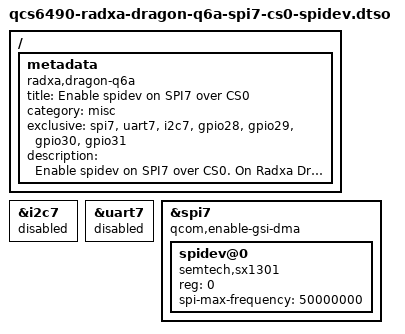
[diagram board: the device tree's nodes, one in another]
// SPDX-License-Identifier: BSD-3-Clause
/*
 * Copyright (c) 2025 Radxa Computer (Shenzhen) Co., Ltd.
 */

/dts-v1/;
/plugin/;

/ {
    metadata {
        title = "Enable spidev on SPI7 over CS0";
        compatible = "radxa,dragon-q6a";
        category = "misc";
        exclusive = "spi7", "uart7", "i2c7", "gpio28", "gpio29", "gpio30", "gpio31";
        description = "Enable spidev on SPI7 over CS0. 
On Radxa Dragon Q6A, this is pin 11(mosi), 29(cs0), 31(miso), 32(sclk).";
    };
};

&i2c7 {
	status = "disabled";
};

&uart7 {
	status = "disabled";
};

&spi7 {
	qcom,enable-gsi-dma;
	status = "okay";
	
	spidev@0 {
		compatible = "semtech,sx1301";
		status = "okay";
		reg = <0>;
		spi-max-frequency = <50000000>;
	};
};
